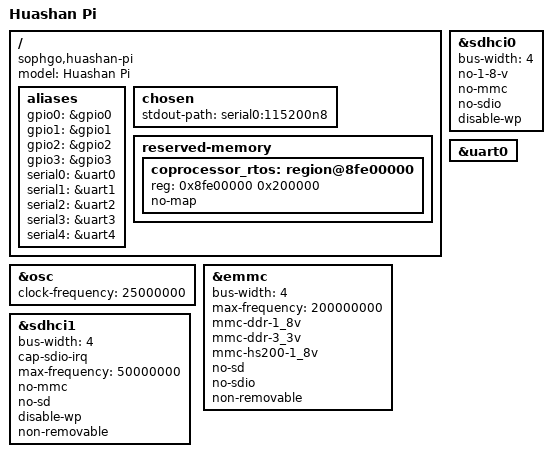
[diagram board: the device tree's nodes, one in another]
// SPDX-License-Identifier: (GPL-2.0 OR MIT)
/*
 * Copyright (C) 2023 Inochi Amaoto <inochiama@outlook.com>
 */

/dts-v1/;

#include "cv1812h.dtsi"

/ {
	model = "Huashan Pi";
	compatible = "sophgo,huashan-pi", "sophgo,cv1812h";

	aliases {
		gpio0 = &gpio0;
		gpio1 = &gpio1;
		gpio2 = &gpio2;
		gpio3 = &gpio3;
		serial0 = &uart0;
		serial1 = &uart1;
		serial2 = &uart2;
		serial3 = &uart3;
		serial4 = &uart4;
	};

	chosen {
		stdout-path = "serial0:115200n8";
	};

	reserved-memory {
		#address-cells = <1>;
		#size-cells = <1>;
		ranges;

		coprocessor_rtos: region@8fe00000 {
			reg = <0x8fe00000 0x200000>;
			no-map;
		};
	};
};

&osc {
	clock-frequency = <25000000>;
};

&emmc {
	status = "okay";
	bus-width = <4>;
	max-frequency = <200000000>;
	mmc-ddr-1_8v;
	mmc-ddr-3_3v;
	mmc-hs200-1_8v;
	no-sd;
	no-sdio;
	non-removable;
};

&sdhci0 {
	status = "okay";
	bus-width = <4>;
	no-1-8-v;
	no-mmc;
	no-sdio;
	disable-wp;
};

&sdhci1 {
	status = "okay";
	bus-width = <4>;
	cap-sdio-irq;
	max-frequency = <50000000>;
	no-mmc;
	no-sd;
	disable-wp;
	non-removable;
};

&uart0 {
	status = "okay";
};
